# ZB204 register map
Vendor: GS; File version: 1.2
CPU: CM3 r2p0, little endian, MPU, no FPU, VTOR, 3 interrupt priority bits
Registers are 32-bit, read-write, reset 0x0 unless marked. A register's access mark holds for its fields unless they carry their own. Offsets are from the block's base; [hi:lo] are bit positions; {n}, {i} and the like mark numbered series; 'fields as' and 'values as' point back to an identical list.

## SCI0 — Serial Communications Interface Module
Base 0x400D0000
Same registers: SCI1 0x400E0000, SCI2 0x400F0000, SCI3 0x40100000
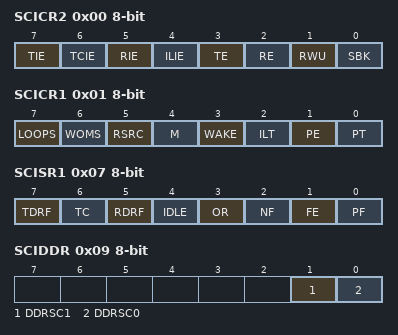
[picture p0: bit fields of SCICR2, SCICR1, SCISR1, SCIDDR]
0x00 SCICR2 8-bit — SCI Control Register 2
  [7] TIE — Transmitter Interrupt Enable Bit
    0=TDRE interrupt requests disabled; 1=TDRE interrupt requests enabled
  [6] TCIE — Transmission Complete Interrupt Enable Bit
    0=TC interrupt requests disabled; 1=TC interrupt requests enabled
  [5] RIE — Receiver Interrupt Enable Bit
    0=RDRF and OR interrupt requests disabled; 1=RDRF and OR interrupt requests enabled
  [4] ILIE — Idle Line Interrupt Enable Bit
    0=IDLE interrupt requests disabled; 1=IDLE interrupt requests enabled
  [3] TE — Transmitter Enable Bit
    0=Transmitter disabled; 1=Transmitter enabled
  [2] RE — Receiver Enable Bit
    0=Receiver disabled; 1=Receiver enabled
  [1] RWU — Receiver Wakeup Bit
    0=Receiver awake when RE = 1; 1=Receiver asleep when RE = 1
  [0] SBK — Send Break Bit
    0=Transmitter does not send break frames; 1=Transmitter sends break frames
0x01 SCICR1 8-bit — SCI Control Register 1
  [7] LOOPS — Loop Select Bit
    0=Normal mode SCI operation; 1=Loop mode SCI operation
  [6] WOMS
    0=TXD and RXD pins open-drain when outputs; 1=TXD and RXD pins CMOS drive when outputs
  [5] RSRC — Receiver Source Bit
    0=Receiver input tied to transmitter output when LOOPS = 1; 1=Receiver input tied to TXD pin when LOOPS = 1
  [4] M — Wakeup Bit
    0=Idle line receiver wakeup; 1=Address mark receiver wakeup
  [3] WAKE — Idle Line Type Bit
    0=Idle frame bit count begins after stop bit; 1=Idle frame bit count begins after start bit
  [2] ILT — Idle Line Type Bit
    0=Parity function enabled; 1=Parity function disabled
  [1] PE — Parity Enable Bit
    0=Parity function disabled; 1=Parity function enabled
  [0] PT — Parity Type Bit
    0=Even parity when PE = 1; 1=Odd parity when PE = 1
0x02 SCIBRDIL 8-bit — SCI Integer Baud-Rate Divisor Register Low
0x03 SCIBRDIH 8-bit — SCI Integer Baud-Rate Divisor Register High
0x04 SCIDRL 8-bit — SCI Data Register Low
0x05 SCIDRH 8-bit — SCI Data Register High
  [6] T_R8 — Receive/Transmit 8 Bit
0x06 SCISR2 8-bit — SCI Status Register 2
  [0] RAF — Receiver Active Flag
    0=No reception in progress; 1=Reception in progress
0x07 SCISR1 8-bit — SCI Status Register 1
  [7] TDRF — Transmit Data Register Empty Flag
    0=Transmission in progress; 1=No transmission in progress
  [6] TC — Transmit Complete Flag
    values as SCICR2.TCIE
  [5] RDRF — Receive Data Register Full Flag
    0=Received data not available in SCIDRH and SCIDRL; 1=Received data available in SCIDRH and SCIDRL
  [4] IDLE — Idle Line Flag
    0=Receiver active or idle since reset or idle since IDLE flag last cleared; 1=Receiver idle
  [3] OR — Overrun Flag
    0=No overrun; 1=Overrun
  [2] NF — Noise Flag
    0=No noise; 1=Noise
  [1] FE — Framing Error Flag
    0=No framing error; 1=Framing error
  [0] PF — Parity Error Flag
    0=No parity error; 1=Parity error
0x08 SCIBRDF 8-bit — SCI Fractional Baud-Rate Divisor Register
0x09 SCIDDR 8-bit — SCI Data Direction Register
  [1] DDRSC1 — TXD PIN
    0=Corresponding pin configured as input; 1=Corresponding pin configured as output
  [0] DDRSC0 — RXD PIN
    values as DDRSC1
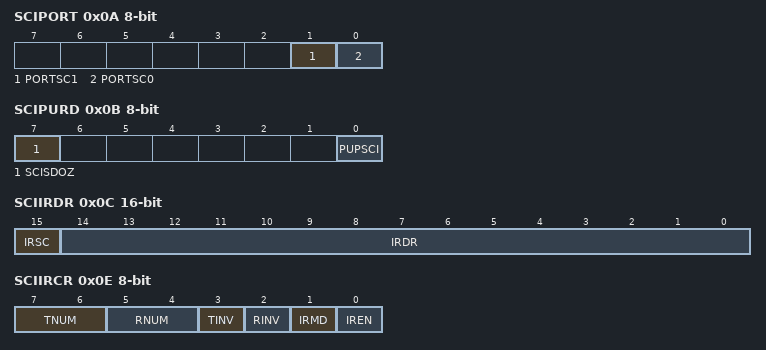
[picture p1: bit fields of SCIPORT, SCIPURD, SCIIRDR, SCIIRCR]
0x0A SCIPORT 8-bit — SCI Port Data Register
  [1] PORTSC1 — TXD PIN
  [0] PORTSC0 — RXD PIN
0x0B SCIPURD 8-bit — SCI Pullup and Reduced Drive Register
  [7] SCISDOZ — SCI Stop in Doze Mode Bit
    1=SCI disabled in doze mode; 0=SCI enabled in doze mode
  [0] PUPSCI — Pullup Enable Bit
    1=TXD and RXD pullups enabled; 0=TXD and RXD pullups disabled
0x0C SCIIRDR 16-bit — SCI InfraRed Divisor Register
  [15] IRSC — InfraRed Interface Sampling Clock Select Bit
    1=divided clock of system clk; 0=baudrate sampling clock
  [14:0] IRDR — SCI InfraRed Divisor
0x0E SCIIRCR 8-bit — SCI InfraRed Control Register
  [7:6] TNUM — Transmission Number Bit
    0=1/16 baudrate; 1=2/16 baudrate; 2=3/16 baudrate
  [5:4] RNUM — Reception Number Bit
    {v}={v+1} times (v=0..3)
  [3] TINV — Inverted Infrared Transmission Bit
    1=Active low; 0=Active high
  [2] RINV — Inverted Infrared Reception Bit
    1=Active high; 0=Active low
  [1] IRMD — InfraRed Interface mode Select Bit
    1=38K; 0=IRDA1.0
  [0] IREN — InfraRed Interface Enable Bit
    1=IR interface enable; 0=IR interface disable
0x0F SCITR 8-bit — SCI Test Register
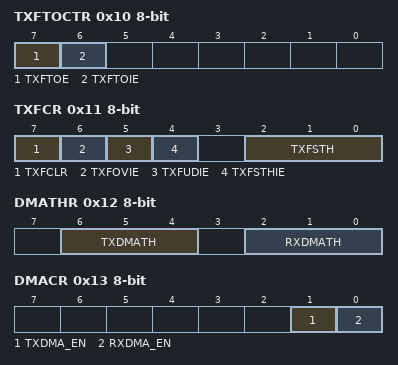
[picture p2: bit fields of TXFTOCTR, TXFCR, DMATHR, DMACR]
0x10 TXFTOCTR 8-bit — SCI FIFO
  [7] TXFTOE, [6] TXFTOIE
0x11 TXFCR 8-bit
  [7] TXFCLR, [6] TXFOVIE, [5] TXFUDIE, [4] TXFSTHIE, [2:0] TXFSTH
0x12 DMATHR 8-bit
  [6:4] TXDMATH, [2:0] RXDMATH
0x13 DMACR 8-bit
  [1] TXDMA_EN, [0] RXDMA_EN
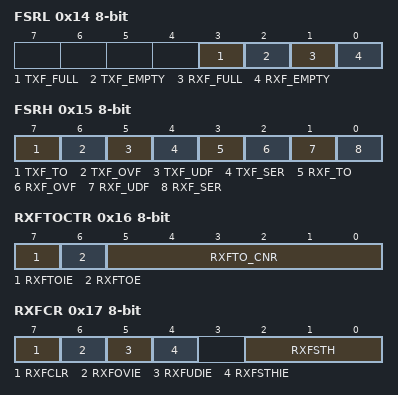
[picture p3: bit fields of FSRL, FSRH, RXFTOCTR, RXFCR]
0x14 FSRL 8-bit
  [3] TXF_FULL, [2] TXF_EMPTY, [1] RXF_FULL, [0] RXF_EMPTY
0x15 FSRH 8-bit
  [7] TXF_TO, [6] TXF_OVF, [5] TXF_UDF, [4] TXF_SER, [3] RXF_TO, [2] RXF_OVF, [1] RXF_UDF, [0] RXF_SER
0x16 RXFTOCTR 8-bit
  [7] RXFTOIE, [6] RXFTOE, [5:0] RXFTO_CNR
0x17 RXFCR 8-bit
  [7] RXFCLR, [6] RXFOVIE, [5] RXFUDIE, [4] RXFSTHIE, [2:0] RXFSTH
0x18 RXFDBGR 8-bit
0x19 TXFDBGR 8-bit
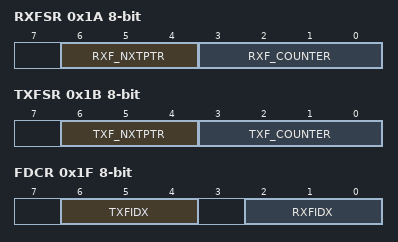
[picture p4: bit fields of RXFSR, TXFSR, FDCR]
0x1A RXFSR 8-bit
  [6:4] RXF_NXTPTR, [3:0] RXF_COUNTER
0x1B TXFSR 8-bit
  [6:4] TXF_NXTPTR, [3:0] TXF_COUNTER
0x1F FDCR 8-bit
  [6:4] TXFIDX, [2:0] RXFIDX
